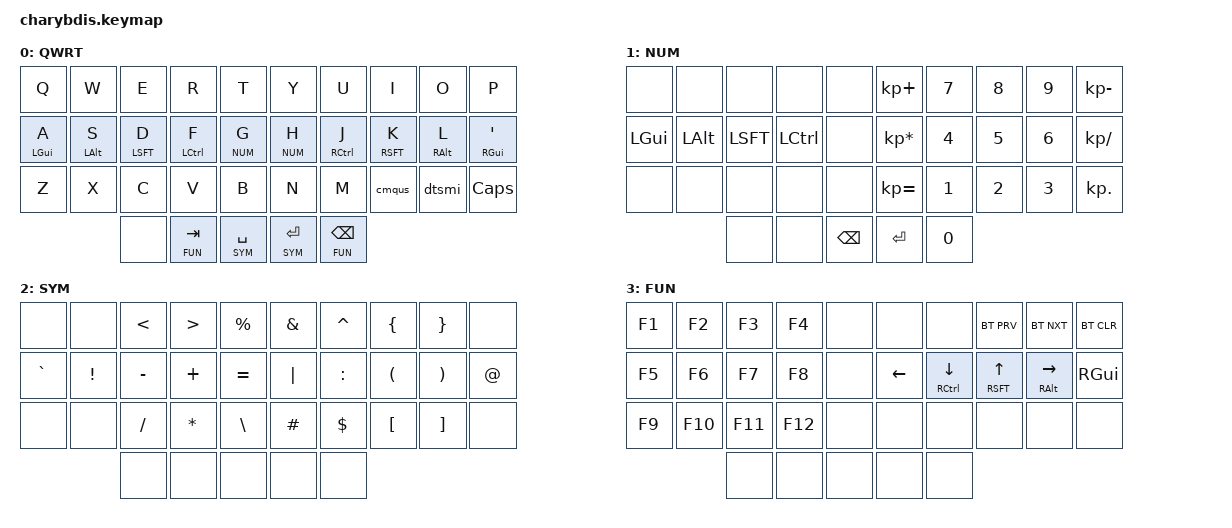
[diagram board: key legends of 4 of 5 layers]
#define DEFAULT 0
#define NUM 1
#define SYM     2
#define FUN     3

#include <behaviors.dtsi>
#include <dt-bindings/zmk/mouse.h>
#include <dt-bindings/zmk/keys.h>
#include <dt-bindings/zmk/bt.h>
#include <dt-bindings/zmk/outputs.h>
#include <dt-bindings/zmk/keys.h>

&lt {
    tapping-term-ms = <240>;
    flavor = "balanced";
    quick-tap-ms = <150>;
};

/ {
    keymap {
        compatible = "zmk,keymap";

        default_layer {
            label = "QWRT";
            bindings = <
            	&kp Q           &kp W           &kp E           &kp R           &kp T           &kp Y           &kp U           &kp I           &kp O           &kp P
             	&mt LGUI A      &mt LALT S      &mt LSFT D      &mt LCTL F      &lt NUM G       &lt NUM H       &mt RCTL J      &mt RSFT K      &mt RALT L      &mt RGUI SQT 
                &kp Z           &kp X           &kp C           &kp V           &kp B           &kp N           &kp M           &cmqus          &dtsmi          &kp CAPS
                                                &none           &lt FUN TAB     &lt SYM SPACE   &lt SYM RET     &lt FUN BSPC
             	>;

            trackball-bindings = <&tmv_coarse>;
        };

        number_layer {
            label = "NUM";
            bindings = <
                &none           &none           &none           &none           &none           &kp KP_PLUS     &kp N7          &kp N8          &kp N9          &kp KP_MINUS
                &kp LGUI        &kp LALT        &kp LSFT        &kp LCTL        &none           &kp KP_MULTIPLY &kp N4          &kp N5          &kp N6          &kp KP_DIVIDE
                &none           &none           &none           &none           &none           &kp KP_EQUAL    &kp N1          &kp N2          &kp N3          &kp KP_DOT
                                                &none           &none           &kp BSPC        &kp RET         &kp N0
            >;
        };

        symbol_layer {
            label = "SYM";
            bindings = <
                &none           &none           &kp LT          &kp GT          &kp PRCNT       &kp AMPS        &kp CARET       &kp LBRC        &kp RBRC        &none
                &kp GRAVE       &kp EXCL        &kp MINUS       &kp PLUS        &kp EQUAL       &kp PIPE        &kp COLON       &kp LPAR        &kp RPAR        &kp AT
                &none           &none           &kp SLASH       &kp STAR        &kp BSLH        &kp HASH        &kp DLLR        &kp LBKT        &kp RBKT        &none  
                                                &none           &none           &none           &none           &none
            >;
        };

        function_layer {
            label = "FUN";
            bindings = <
                &kp F1           &kp F2         &kp F3          &kp F4          &none           &none           &none           &bt BT_PRV      &bt BT_NXT      &bt BT_CLR 
                &kp F5           &kp F6         &kp F7          &kp F8          &none           &kp LEFT        &mt RCTL DOWN   &mt RSFT UP     &mt RALT RIGHT  &kp RGUI
                &kp F9           &kp F10        &kp F11         &kp F12         &none           &none           &none           &none           &none           &none
                                                &none           &none           &none           &none           &none
            >;
        };

        mouse_layer {
            bindings = <
                &kp F5           &kp F6         &kp F7          &kp F8          &none           &kp LEFT        &mt RCTL DOWN   &mt RSFT UP     &mt RALT RIGHT  &kp RGUI
                &trans           &trans         &trans          &trans          &trans          &trans          &trans          &trans          &trans          &trans
                &trans           &trans         &trans          &trans          &trans          &trans          &trans          &trans          &trans          &trans
                &mkp MCLK        &trans         &trans          &trans          &trans          &trans          &trans          &trans          &trans          &mkp LCLK
                                                &mkp LCLK       &trans          &mkp RCLK       &trans          &trans
            >;
        };
    };
};
